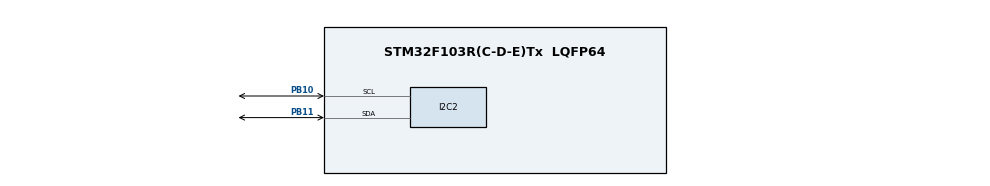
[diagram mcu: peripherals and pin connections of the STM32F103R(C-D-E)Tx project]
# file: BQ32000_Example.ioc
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Mcu.Family=STM32F1
Mcu.Name=STM32F103R(C-D-E)Tx
Mcu.Package=LQFP64
NVIC.PriorityGroup=NVIC_PRIORITYGROUP_4
PA13.Mode=Serial_Wire
PA13.Signal=SYS_JTMS-SWDIO
PA14.Mode=Serial_Wire
PA14.Signal=SYS_JTCK-SWCLK
PB10.Mode=I2C
PB10.Signal=I2C2_SCL
PB11.Mode=I2C
PB11.Signal=I2C2_SDA
ProjectManager.HeapSize=0x200
ProjectManager.StackSize=0x400
ProjectManager.TargetToolchain=STM32CubeIDE
RCC.APB1Freq_Value=8000000
RCC.APB2Freq_Value=8000000
board=custom

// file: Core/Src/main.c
/* USER CODE BEGIN Header */
/**
  ******************************************************************************
  * @file           : main.c
  * @brief          : Main program body
  ******************************************************************************
  * @attention
  *
  * Copyright (c) 2023 STMicroelectronics.
  * All rights reserved.
  *
  * This software is licensed under terms that can be found in the LICENSE file
  * in the root directory of this software component.
  * If no LICENSE file comes with this software, it is provided AS-IS.
  *
  ******************************************************************************
  */
/* USER CODE END Header */
#include "main.h"

/* USER CODE BEGIN Includes */
#include "rtc_bq32000.h"
/* USER CODE END Includes */

I2C_HandleTypeDef hi2c2;

void SystemClock_Config(void);
static void MX_GPIO_Init(void);
static void MX_I2C2_Init(void);

int main(void)
{

  /* MCU Configuration--------------------------------------------------------*/

  /* Reset of all peripherals, Initializes the Flash interface and the Systick. */
  HAL_Init();

  /* USER CODE BEGIN Init */
  RTC_BQ32000_Init(&hi2c2);
  /* USER CODE END Init */

  /* Configure the system clock */
  SystemClock_Config();

  /* Initialize all configured peripherals */
  MX_GPIO_Init();
  MX_I2C2_Init();
  /* USER CODE BEGIN 2 */
  // Set the RTC time (example time: 12:34:56, Monday, 20th November 2023)
  //setTime = {Seconds, Minutes, Hour, week, date, month, year}
     RTC_Time setTime = {00, 54, 8, 5, 17, 11, 23};
   HAL_StatusTypeDef statusSet = RTC_BQ32000_SetTime(&hi2c2, &setTime);

//   if (statusSet == HAL_OK) {
//       // Time set successfully
//   } else {
//       // Error handling
//   }
  /* USER CODE END 2 */

  /* Infinite loop */
  while (1)
  {
	  RTC_BQ32000_ReadTime(&hi2c2, &globalRTC_Time);
	  HAL_Delay(1000);
  }
}

void SystemClock_Config(void)
{
  RCC_OscInitTypeDef RCC_OscInitStruct = {0};
  RCC_ClkInitTypeDef RCC_ClkInitStruct = {0};

  /** Initializes the RCC Oscillators according to the specified parameters
  * in the RCC_OscInitTypeDef structure.
  */
  RCC_OscInitStruct.OscillatorType = RCC_OSCILLATORTYPE_HSI;
  RCC_OscInitStruct.HSIState = RCC_HSI_ON;
  RCC_OscInitStruct.HSICalibrationValue = RCC_HSICALIBRATION_DEFAULT;
  RCC_OscInitStruct.PLL.PLLState = RCC_PLL_NONE;
  if (HAL_RCC_OscConfig(&RCC_OscInitStruct) != HAL_OK)
  {
    Error_Handler();
  }

  /** Initializes the CPU, AHB and APB buses clocks
  */
  RCC_ClkInitStruct.ClockType = RCC_CLOCKTYPE_HCLK|RCC_CLOCKTYPE_SYSCLK
                              |RCC_CLOCKTYPE_PCLK1|RCC_CLOCKTYPE_PCLK2;
  RCC_ClkInitStruct.SYSCLKSource = RCC_SYSCLKSOURCE_HSI;
  RCC_ClkInitStruct.AHBCLKDivider = RCC_SYSCLK_DIV1;
  RCC_ClkInitStruct.APB1CLKDivider = RCC_HCLK_DIV1;
  RCC_ClkInitStruct.APB2CLKDivider = RCC_HCLK_DIV1;

  if (HAL_RCC_ClockConfig(&RCC_ClkInitStruct, FLASH_LATENCY_0) != HAL_OK)
  {
    Error_Handler();
  }
}

static void MX_I2C2_Init(void)
{

  hi2c2.Instance = I2C2;
  hi2c2.Init.ClockSpeed = 100000;
  hi2c2.Init.DutyCycle = I2C_DUTYCYCLE_2;
  hi2c2.Init.OwnAddress1 = 0;
  hi2c2.Init.AddressingMode = I2C_ADDRESSINGMODE_7BIT;
  hi2c2.Init.DualAddressMode = I2C_DUALADDRESS_DISABLE;
  hi2c2.Init.OwnAddress2 = 0;
  hi2c2.Init.GeneralCallMode = I2C_GENERALCALL_DISABLE;
  hi2c2.Init.NoStretchMode = I2C_NOSTRETCH_DISABLE;
  if (HAL_I2C_Init(&hi2c2) != HAL_OK)
  {
    Error_Handler();
  }

}

static void MX_GPIO_Init(void)
{

  /* GPIO Ports Clock Enable */
  __HAL_RCC_GPIOB_CLK_ENABLE();
  __HAL_RCC_GPIOA_CLK_ENABLE();

}

void Error_Handler(void)
{
  __disable_irq();
  while (1)
  {
  }
}
